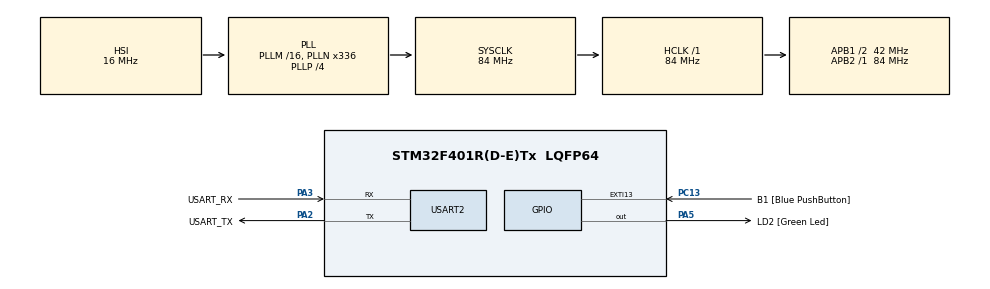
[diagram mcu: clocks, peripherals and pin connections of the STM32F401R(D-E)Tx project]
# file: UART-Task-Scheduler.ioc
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FREERTOS.Tasks01=Led_Blink_task,24,128,Led_Blink,Default,NULL,Dynamic,NULL,NULL;USART_Task,16,128,Uart_Task,Default,NULL,Dynamic,NULL,NULL
Mcu.Family=STM32F4
Mcu.Name=STM32F401R(D-E)Tx
Mcu.Package=LQFP64
NVIC.PriorityGroup=NVIC_PRIORITYGROUP_4
PA13.GPIO_Label=TMS
PA13.Mode=Trace_Asynchronous_SW
PA13.Signal=SYS_JTMS-SWDIO
PA14.GPIO_Label=TCK
PA14.Mode=Trace_Asynchronous_SW
PA14.Signal=SYS_JTCK-SWCLK
PA2.GPIO_Label=USART_TX
PA2.GPIO_Mode=GPIO_MODE_AF_PP
PA2.GPIO_PuPd=GPIO_NOPULL
PA2.GPIO_Speed=GPIO_SPEED_FREQ_LOW
PA2.Mode=Asynchronous
PA2.Signal=USART2_TX
PA3.GPIO_Label=USART_RX
PA3.GPIO_Mode=GPIO_MODE_AF_PP
PA3.GPIO_PuPd=GPIO_NOPULL
PA3.GPIO_Speed=GPIO_SPEED_FREQ_LOW
PA3.Mode=Asynchronous
PA3.Signal=USART2_RX
PA5.GPIO_Label=LD2 [Green Led]
PA5.GPIO_Mode=GPIO_MODE_OUTPUT_PP
PA5.GPIO_PuPd=GPIO_NOPULL
PA5.GPIO_Speed=GPIO_SPEED_FREQ_LOW
PA5.Signal=GPIO_Output
PB3.GPIO_Label=SWO
PB3.Mode=Trace_Asynchronous_SW
PB3.Signal=SYS_JTDO-SWO
PC13-ANTI_TAMP.GPIO_Label=B1 [Blue PushButton]
PC13-ANTI_TAMP.GPIO_ModeDefaultEXTI=GPIO_MODE_IT_FALLING
PC13-ANTI_TAMP.GPIO_PuPd=GPIO_NOPULL
PC13-ANTI_TAMP.Signal=GPXTI13
PC14-OSC32_IN.Mode=LSE-External-Oscillator
PC14-OSC32_IN.Signal=RCC_OSC32_IN
PC15-OSC32_OUT.Mode=LSE-External-Oscillator
PC15-OSC32_OUT.Signal=RCC_OSC32_OUT
PH0\ -\ OSC_IN.Mode=HSE-External-Clock-Source
PH0\ -\ OSC_IN.Signal=RCC_OSC_IN
PH1\ -\ OSC_OUT.Mode=HSE-External-Clock-Source
PH1\ -\ OSC_OUT.Signal=RCC_OSC_OUT
ProjectManager.HeapSize=0x200
ProjectManager.StackSize=0x400
ProjectManager.TargetToolchain=STM32CubeIDE
RCC.48MHZClocksFreq_Value=48000000
RCC.AHBFreq_Value=84000000
RCC.APB1CLKDivider=RCC_HCLK_DIV2
RCC.APB1Freq_Value=42000000
RCC.APB1TimFreq_Value=84000000
RCC.APB2Freq_Value=84000000
RCC.APB2TimFreq_Value=84000000
RCC.CortexFreq_Value=84000000
RCC.HCLKFreq_Value=84000000
RCC.HSE_VALUE=8000000
RCC.HSI_VALUE=16000000
RCC.PLLN=336
RCC.PLLP=RCC_PLLP_DIV4
RCC.PLLQ=7
RCC.SYSCLKFreq_VALUE=84000000
RCC.SYSCLKSource=RCC_SYSCLKSOURCE_PLLCLK
RCC.VCOOutputFreq_Value=336000000
USART2.VirtualMode=VM_ASYNC
VP_FREERTOS_VS_CMSIS_V2.Mode=CMSIS_V2
board=NUCLEO-F401RE

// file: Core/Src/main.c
/* USER CODE BEGIN Header */
/**
  ******************************************************************************
  * @file           : main.c
  * @brief          : Main program body
  ******************************************************************************
  * @attention
  *
  * Copyright (c) 2025 STMicroelectronics.
  * All rights reserved.
  *
  * This software is licensed under terms that can be found in the LICENSE file
  * in the root directory of this software component.
  * If no LICENSE file comes with this software, it is provided AS-IS.
  *
  ******************************************************************************
  */
/* USER CODE END Header */
#include "main.h"
#include "cmsis_os.h"
#include <stdint.h>
#include<string.h>
#include "queue.h"

UART_HandleTypeDef huart2;
QueueHandle_t delay_Queue;
/* Definitions for Led_Blink_task */
osThreadId_t Led_Blink_taskHandle;
const osThreadAttr_t Led_Blink_task_attributes = {
  .name = "Led_Blink_task",
  .stack_size = 128 * 4,
  .priority = (osPriority_t) osPriorityNormal,
};
/* Definitions for USART_Task */
osThreadId_t USART_TaskHandle;
const osThreadAttr_t USART_Task_attributes = {
  .name = "USART_Task",
  .stack_size = 128 * 4,
  .priority = (osPriority_t) osPriorityBelowNormal,
};

void SystemClock_Config(void);
static void MX_GPIO_Init(void);
static void MX_USART2_UART_Init(void);
void Led_Blink(void *argument);
void Uart_Task(void *argument);

int main(void)
{

  /* USER CODE END 1 */

  /* MCU Configuration--------------------------------------------------------*/

  /* Reset of all peripherals, Initializes the Flash interface and the Systick. */
  HAL_Init();

  /* Configure the system clock */
  SystemClock_Config();

  /* Initialize all configured peripherals */
  MX_GPIO_Init();
  MX_USART2_UART_Init();
  /* USER CODE BEGIN 2 */

    /* USER CODE BEGIN 1 */
  	delay_Queue = xQueueCreate(5, sizeof(int));

  	if (delay_Queue == NULL) {
  	    // Queue not created, handle error
  	    Error_Handler();
  	}

  	//UART_Send_String("Enter to Update   LED  Delay\n");
  /* USER CODE END 2 */

  /* Init scheduler */
  osKernelInitialize();

  /* Create the thread(s) */
  /* creation of Led_Blink_task */
  Led_Blink_taskHandle = osThreadNew(Led_Blink, NULL, &Led_Blink_task_attributes);

  /* creation of USART_Task */
  USART_TaskHandle = osThreadNew(Uart_Task, NULL, &USART_Task_attributes);

  /* Start scheduler */
  osKernelStart();

  /* We should never get here as control is now taken by the scheduler */

  /* Infinite loop */
  while (1)
  {

  }
}

void SystemClock_Config(void)
{
  RCC_OscInitTypeDef RCC_OscInitStruct = {0};
  RCC_ClkInitTypeDef RCC_ClkInitStruct = {0};

  /** Configure the main internal regulator output voltage
  */
  __HAL_RCC_PWR_CLK_ENABLE();
  __HAL_PWR_VOLTAGESCALING_CONFIG(PWR_REGULATOR_VOLTAGE_SCALE2);

  /** Initializes the RCC Oscillators according to the specified parameters
  * in the RCC_OscInitTypeDef structure.
  */
  RCC_OscInitStruct.OscillatorType = RCC_OSCILLATORTYPE_HSI;
  RCC_OscInitStruct.HSIState = RCC_HSI_ON;
  RCC_OscInitStruct.HSICalibrationValue = RCC_HSICALIBRATION_DEFAULT;
  RCC_OscInitStruct.PLL.PLLState = RCC_PLL_ON;
  RCC_OscInitStruct.PLL.PLLSource = RCC_PLLSOURCE_HSI;
  RCC_OscInitStruct.PLL.PLLM = 16;
  RCC_OscInitStruct.PLL.PLLN = 336;
  RCC_OscInitStruct.PLL.PLLP = RCC_PLLP_DIV4;
  RCC_OscInitStruct.PLL.PLLQ = 7;
  if (HAL_RCC_OscConfig(&RCC_OscInitStruct) != HAL_OK)
  {
    Error_Handler();
  }

  /** Initializes the CPU, AHB and APB buses clocks
  */
  RCC_ClkInitStruct.ClockType = RCC_CLOCKTYPE_HCLK|RCC_CLOCKTYPE_SYSCLK
                              |RCC_CLOCKTYPE_PCLK1|RCC_CLOCKTYPE_PCLK2;
  RCC_ClkInitStruct.SYSCLKSource = RCC_SYSCLKSOURCE_PLLCLK;
  RCC_ClkInitStruct.AHBCLKDivider = RCC_SYSCLK_DIV1;
  RCC_ClkInitStruct.APB1CLKDivider = RCC_HCLK_DIV2;
  RCC_ClkInitStruct.APB2CLKDivider = RCC_HCLK_DIV1;

  if (HAL_RCC_ClockConfig(&RCC_ClkInitStruct, FLASH_LATENCY_2) != HAL_OK)
  {
    Error_Handler();
  }
}

static void MX_USART2_UART_Init(void)
{

  huart2.Instance = USART2;
  huart2.Init.BaudRate = 115200;
  huart2.Init.WordLength = UART_WORDLENGTH_8B;
  huart2.Init.StopBits = UART_STOPBITS_1;
  huart2.Init.Parity = UART_PARITY_NONE;
  huart2.Init.Mode = UART_MODE_TX_RX;
  huart2.Init.HwFlowCtl = UART_HWCONTROL_NONE;
  huart2.Init.OverSampling = UART_OVERSAMPLING_16;
  if (HAL_UART_Init(&huart2) != HAL_OK)
  {
    Error_Handler();
  }

}

static void MX_GPIO_Init(void)
{
  GPIO_InitTypeDef GPIO_InitStruct = {0};

  /* GPIO Ports Clock Enable */
  __HAL_RCC_GPIOC_CLK_ENABLE();
  __HAL_RCC_GPIOH_CLK_ENABLE();
  __HAL_RCC_GPIOA_CLK_ENABLE();
  __HAL_RCC_GPIOB_CLK_ENABLE();

  /*Configure GPIO pin Output Level */
  HAL_GPIO_WritePin(LD2_GPIO_Port, LD2_Pin, GPIO_PIN_RESET);

  /*Configure GPIO pin : B1_Pin */
  GPIO_InitStruct.Pin = B1_Pin;
  GPIO_InitStruct.Mode = GPIO_MODE_IT_FALLING;
  GPIO_InitStruct.Pull = GPIO_NOPULL;
  HAL_GPIO_Init(B1_GPIO_Port, &GPIO_InitStruct);

  /*Configure GPIO pin : LD2_Pin */
  GPIO_InitStruct.Pin = LD2_Pin;
  GPIO_InitStruct.Mode = GPIO_MODE_OUTPUT_PP;
  GPIO_InitStruct.Pull = GPIO_NOPULL;
  GPIO_InitStruct.Speed = GPIO_SPEED_FREQ_LOW;
  HAL_GPIO_Init(LD2_GPIO_Port, &GPIO_InitStruct);

}

/* USER CODE BEGIN 4 */
void UART_Send_String(char *str)
{
    HAL_UART_Transmit(&huart2, (uint8_t*)str, strlen(str), HAL_MAX_DELAY);
}

/* USER CODE END 4 */

void Led_Blink(void *argument)
{
  /* USER CODE BEGIN 5 */
	uint32_t Default_delay = 500;
	uint32_t New_delay ;

 while(1)
 {
	 if(xQueueReceive(delay_Queue, &New_delay, 0) == pdPASS)
	 {
		 Default_delay = New_delay;
	 }
	 HAL_GPIO_TogglePin(GPIOA, GPIO_PIN_5);
	vTaskDelay(pdMS_TO_TICKS(Default_delay));
 }
  /* USER CODE END 5 */
}

//void Uart_Task(void *argument)
//{
//  /* USER CODE BEGIN Uart_Task */
//	 uint8_t buffer[50];
//	 uint32_t New_Delay;
//  while(1)
//  {
//	  memset(buffer, 0, sizeof(buffer));  // clear old data
//	 HAL_UART_Receive(&huart2,(uint8_t *) buffer, sizeof(buffer), HAL_MAX_DELAY);
//	 New_Delay = atoi(buffer);
//
//	 if(New_Delay > 0)
//	 {
//
//		 char msg[50];
//		 xQueueSend(delay_Queue, &New_Delay,portMAX_DELAY);
//		 sprintf(msg, "LED delay Updated to %d\r\n", New_Delay);
//		 HAL_UART_Transmit(&huart2, (uint8_t*)msg, strlen(msg), HAL_MAX_DELAY);
//
//	 }
//	 else
//	 {
//	             UART_Send_String("Invalid input. Please enter a number > 0\r\n");
//	    }
//  }
//  /* USER CODE END Uart_Task */
//}

void Uart_Task(void *argument)
{
    uint8_t rxChar;
    uint8_t buffer[20];
    uint8_t index = 0;
    uint32_t New_Delay;

    UART_Send_String("Ready for input. Type delay and press Enter:\r\n");

    while(1)
    {
        // Receive one character at a time
        if(HAL_UART_Receive(&huart2, &rxChar, 1, HAL_MAX_DELAY) == HAL_OK)
        {

            if(rxChar == '\r' || rxChar == '\n')
            {
                buffer[index] = '\0'; // Null terminate the string
                UART_Send_String("\r\n");

                New_Delay = atoi((char*)buffer);

                if(New_Delay > 0)
                {
                    char msg[50];
                    xQueueSend(delay_Queue, &New_Delay, portMAX_DELAY);
                    sprintf(msg, "LED delay updated to %lu ms\r\n", New_Delay);
                    HAL_UART_Transmit(&huart2, (uint8_t*)msg, strlen(msg), HAL_MAX_DELAY);
                }
                else
                {
                    UART_Send_String("Invalid input. Please enter a number > 0\r\n");
                }

                // Reset buffer for next input
                memset(buffer, 0, sizeof(buffer));
                index = 0;
                UART_Send_String("Enter new delay: ");
            }
            else if(rxChar >= '0' && rxChar <= '9')
            {
                if(index < sizeof(buffer) - 1)
                {
                    buffer[index++] = rxChar;
                }
            }
            else if(rxChar == 8 || rxChar == 127)
            {
                if(index > 0)
                {
                    index--;
                    UART_Send_String("\b \b");
                }
            }
        }
    }
}

void Error_Handler(void)
{
  __disable_irq();
  while (1)
  {
  }
}
